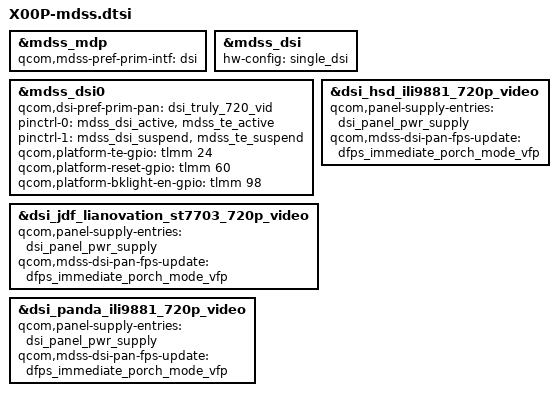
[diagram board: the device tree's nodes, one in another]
/*
 * Copyright (c) 2015-2017, The Linux Foundation. All rights reserved.
 *
 * This program is free software; you can redistribute it and/or modify
 * it under the terms of the GNU General Public License version 2 and
 * only version 2 as published by the Free Software Foundation.
 *
 * This program is distributed in the hope that it will be useful,
 * but WITHOUT ANY WARRANTY; without even the implied warranty of
 * MERCHANTABILITY or FITNESS FOR A PARTICULAR PURPOSE.  See the
 * GNU General Public License for more details.
 */

/* msm8937-mdss-panels */
#include "dsi-panel-ili9881c-cpt-video.dtsi"
#include "dsi_panel_st7703_jdf_lianovation_video.dtsi"	
#include "dsi-panel-ili9881c-hsd-video.dtsi"
#include "dsi-panel-ili9881p-panda-ykl.dtsi"

&mdss_mdp {
	qcom,mdss-pref-prim-intf = "dsi";
};

&mdss_dsi {
	hw-config = "single_dsi";
};

&mdss_dsi0 {
	qcom,dsi-pref-prim-pan = <&dsi_truly_720_vid>;
	//qcom,dsi-pref-prim-pan = <&dsi_hsd_ili9881_720p_video>;
	//qcom,dsi-pref-prim-pan = <&dsi_jdf_lianovation_st7703_720p_video>;
	pinctrl-names = "mdss_default", "mdss_sleep";
	pinctrl-0 = <&mdss_dsi_active &mdss_te_active>;
	pinctrl-1 = <&mdss_dsi_suspend &mdss_te_suspend>;
	qcom,platform-te-gpio = <&tlmm 24 0>;
	qcom,platform-reset-gpio = <&tlmm 60 0>;
	qcom,platform-bklight-en-gpio = <&tlmm 98 0>;
};

&dsi_hsd_ili9881_720p_video {
	qcom,panel-supply-entries = <&dsi_panel_pwr_supply>;
	//qcom,mdss-dsi-pan-enable-dynamic-fps;
	qcom,mdss-dsi-pan-fps-update = "dfps_immediate_porch_mode_vfp";
};

&dsi_jdf_lianovation_st7703_720p_video {
	qcom,panel-supply-entries = <&dsi_panel_pwr_supply>;
	//qcom,mdss-dsi-pan-enable-dynamic-fps;
	qcom,mdss-dsi-pan-fps-update = "dfps_immediate_porch_mode_vfp";
};

&dsi_panda_ili9881_720p_video {
	qcom,panel-supply-entries = <&dsi_panel_pwr_supply>;
	//qcom,mdss-dsi-pan-enable-dynamic-fps;
	qcom,mdss-dsi-pan-fps-update = "dfps_immediate_porch_mode_vfp";
};
